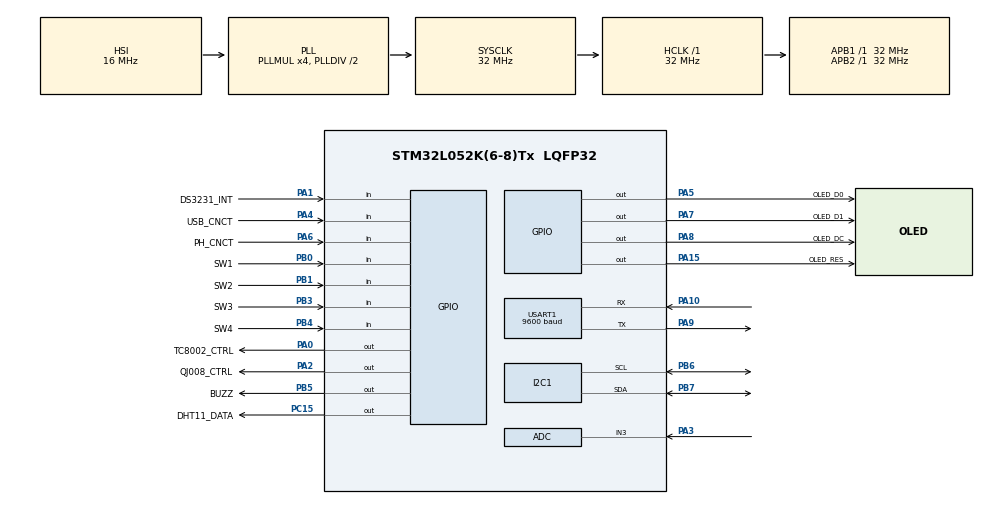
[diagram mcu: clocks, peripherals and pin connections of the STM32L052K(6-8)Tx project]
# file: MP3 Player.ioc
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ADC.ContinuousConvMode=ENABLE
ADC.SamplingTime=ADC_SAMPLETIME_160CYCLES_5
I2C1.Timing=0x00707CBB
Mcu.Family=STM32L0
Mcu.Name=STM32L052K(6-8)Tx
Mcu.Package=LQFP32
NVIC.TIM2_IRQn=true\:0\:0\:false\:false\:true\:true\:true\:true
NVIC.USART1_IRQn=true\:0\:0\:false\:false\:true\:true\:true\:true
PA0.GPIO_Label=TC8002_CTRL
PA0.GPIO_ModeDefaultOutputPP=GPIO_MODE_OUTPUT_OD
PA0.GPIO_PuPd=GPIO_NOPULL
PA0.GPIO_Speed=GPIO_SPEED_FREQ_VERY_HIGH
PA0.Signal=GPIO_Output
PA1.GPIO_Label=DS3231_INT
PA1.GPIO_PuPd=GPIO_PULLUP
PA1.Signal=GPIO_Input
PA10.Mode=Asynchronous
PA10.Signal=USART1_RX
PA13.Mode=Serial_Wire
PA13.Signal=SYS_SWDIO
PA14.Mode=Serial_Wire
PA14.Signal=SYS_SWCLK
PA15.GPIO_Label=OLED_RES
PA15.GPIO_Speed=GPIO_SPEED_FREQ_VERY_HIGH
PA15.Signal=GPIO_Output
PA2.GPIO_Label=QJ008_CTRL
PA2.GPIO_ModeDefaultOutputPP=GPIO_MODE_OUTPUT_OD
PA2.GPIO_PuPd=GPIO_NOPULL
PA2.GPIO_Speed=GPIO_SPEED_FREQ_VERY_HIGH
PA2.Signal=GPIO_Output
PA3.Mode=IN3
PA3.Signal=ADC_IN3
PA4.GPIO_Label=USB_CNCT
PA4.GPIO_PuPd=GPIO_PULLDOWN
PA4.Signal=GPIO_Input
PA5.GPIO_Label=OLED_D0
PA5.GPIO_Speed=GPIO_SPEED_FREQ_VERY_HIGH
PA5.Signal=GPIO_Output
PA6.GPIO_Label=PH_CNCT
PA6.Signal=GPIO_Input
PA7.GPIO_Label=OLED_D1
PA7.GPIO_Speed=GPIO_SPEED_FREQ_VERY_HIGH
PA7.Signal=GPIO_Output
PA8.GPIO_Label=OLED_DC
PA8.GPIO_Speed=GPIO_SPEED_FREQ_VERY_HIGH
PA8.Signal=GPIO_Output
PA9.Mode=Asynchronous
PA9.Signal=USART1_TX
PB0.GPIO_Label=SW1
PB0.GPIO_PuPd=GPIO_PULLUP
PB0.Signal=GPIO_Input
PB1.GPIO_Label=SW2
PB1.GPIO_PuPd=GPIO_PULLUP
PB1.Signal=GPIO_Input
PB3.GPIO_Label=SW3
PB3.GPIO_PuPd=GPIO_PULLUP
PB3.Signal=GPIO_Input
PB4.GPIO_Label=SW4
PB4.GPIO_PuPd=GPIO_PULLUP
PB4.Signal=GPIO_Input
PB5.GPIO_Label=BUZZ
PB5.GPIO_Speed=GPIO_SPEED_FREQ_VERY_HIGH
PB5.Signal=GPIO_Output
PB6.GPIO_Pu=GPIO_PULLUP
PB6.Mode=I2C
PB6.Signal=I2C1_SCL
PB7.GPIO_Pu=GPIO_PULLUP
PB7.Mode=I2C
PB7.Signal=I2C1_SDA
PC15-OSC32_OUT.GPIO_Label=DHT11_DATA
PC15-OSC32_OUT.GPIO_Speed=GPIO_SPEED_FREQ_VERY_HIGH
PC15-OSC32_OUT.PinState=GPIO_PIN_SET
PC15-OSC32_OUT.Signal=GPIO_Output
ProjectManager.HeapSize=0x200
ProjectManager.StackSize=0x400
ProjectManager.TargetToolchain=STM32CubeIDE
RCC.AHBFreq_Value=32000000
RCC.APB1Freq_Value=32000000
RCC.APB1TimFreq_Value=32000000
RCC.APB2Freq_Value=32000000
RCC.APB2TimFreq_Value=32000000
RCC.HCLKFreq_Value=32000000
RCC.HSI16_VALUE=16000000
RCC.HSI48_VALUE=48000000
RCC.HSI_VALUE=16000000
RCC.LSE_VALUE=32768
RCC.MSI_VALUE=2097000
RCC.PLLMUL=RCC_PLLMUL_4
RCC.SYSCLKFreq_VALUE=32000000
RCC.SYSCLKSource=RCC_SYSCLKSOURCE_PLLCLK
RCC.VCOOutputFreq_Value=64000000
TIM2.Period=10000-1
TIM2.Prescaler=32-1
USART1.BaudRate=9600
USART1.VirtualMode-Asynchronous=VM_ASYNC
VP_TIM2_VS_ClockSourceINT.Mode=Internal
board=custom

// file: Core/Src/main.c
/* USER CODE BEGIN Header */
/**
  ******************************************************************************
  * @file           : main.c
  * @brief          : Main program body
  ******************************************************************************
  * @attention
  *
  * Copyright (c) 2022 STMicroelectronics.
  * All rights reserved.
  *
  * This software is licensed under terms that can be found in the LICENSE file
  * in the root directory of this software component.
  * If no LICENSE file comes with this software, it is provided AS-IS.
  *
  ******************************************************************************
  */
/* USER CODE END Header */
#include "main.h"

/* USER CODE BEGIN Includes */
#include "User_Tasks.h"
/* USER CODE END Includes */

ADC_HandleTypeDef hadc;

I2C_HandleTypeDef hi2c1;

TIM_HandleTypeDef htim2;

UART_HandleTypeDef huart1;

void SystemClock_Config(void);
static void MX_GPIO_Init(void);
static void MX_ADC_Init(void);
static void MX_I2C1_Init(void);
static void MX_USART1_UART_Init(void);
static void MX_TIM2_Init(void);

int main(void)
{

  /* MCU Configuration--------------------------------------------------------*/

  /* Reset of all peripherals, Initializes the Flash interface and the Systick. */
  HAL_Init();

  /* Configure the system clock */
  SystemClock_Config();

  /* Initialize all configured peripherals */
  MX_GPIO_Init();
  MX_ADC_Init();
  MX_I2C1_Init();
  MX_USART1_UART_Init();
  MX_TIM2_Init();
  /* USER CODE BEGIN 2 */
  HAL_TIM_Base_Start_IT(&htim2);
  loop();
  /* USER CODE END 2 */

  /* Infinite loop */
  while (1)
  {

  }
}

void SystemClock_Config(void)
{
  RCC_OscInitTypeDef RCC_OscInitStruct = {0};
  RCC_ClkInitTypeDef RCC_ClkInitStruct = {0};
  RCC_PeriphCLKInitTypeDef PeriphClkInit = {0};

  /** Configure the main internal regulator output voltage
  */
  __HAL_PWR_VOLTAGESCALING_CONFIG(PWR_REGULATOR_VOLTAGE_SCALE1);

  /** Initializes the RCC Oscillators according to the specified parameters
  * in the RCC_OscInitTypeDef structure.
  */
  RCC_OscInitStruct.OscillatorType = RCC_OSCILLATORTYPE_HSI;
  RCC_OscInitStruct.HSIState = RCC_HSI_ON;
  RCC_OscInitStruct.HSICalibrationValue = RCC_HSICALIBRATION_DEFAULT;
  RCC_OscInitStruct.PLL.PLLState = RCC_PLL_ON;
  RCC_OscInitStruct.PLL.PLLSource = RCC_PLLSOURCE_HSI;
  RCC_OscInitStruct.PLL.PLLMUL = RCC_PLLMUL_4;
  RCC_OscInitStruct.PLL.PLLDIV = RCC_PLLDIV_2;
  if (HAL_RCC_OscConfig(&RCC_OscInitStruct) != HAL_OK)
  {
    Error_Handler();
  }

  /** Initializes the CPU, AHB and APB buses clocks
  */
  RCC_ClkInitStruct.ClockType = RCC_CLOCKTYPE_HCLK|RCC_CLOCKTYPE_SYSCLK
                              |RCC_CLOCKTYPE_PCLK1|RCC_CLOCKTYPE_PCLK2;
  RCC_ClkInitStruct.SYSCLKSource = RCC_SYSCLKSOURCE_PLLCLK;
  RCC_ClkInitStruct.AHBCLKDivider = RCC_SYSCLK_DIV1;
  RCC_ClkInitStruct.APB1CLKDivider = RCC_HCLK_DIV1;
  RCC_ClkInitStruct.APB2CLKDivider = RCC_HCLK_DIV1;

  if (HAL_RCC_ClockConfig(&RCC_ClkInitStruct, FLASH_LATENCY_1) != HAL_OK)
  {
    Error_Handler();
  }
  PeriphClkInit.PeriphClockSelection = RCC_PERIPHCLK_USART1|RCC_PERIPHCLK_I2C1;
  PeriphClkInit.Usart1ClockSelection = RCC_USART1CLKSOURCE_PCLK2;
  PeriphClkInit.I2c1ClockSelection = RCC_I2C1CLKSOURCE_PCLK1;
  if (HAL_RCCEx_PeriphCLKConfig(&PeriphClkInit) != HAL_OK)
  {
    Error_Handler();
  }
}

static void MX_ADC_Init(void)
{

  ADC_ChannelConfTypeDef sConfig = {0};

  /** Configure the global features of the ADC (Clock, Resolution, Data Alignment and number of conversion)
  */
  hadc.Instance = ADC1;
  hadc.Init.OversamplingMode = DISABLE;
  hadc.Init.ClockPrescaler = ADC_CLOCK_SYNC_PCLK_DIV2;
  hadc.Init.Resolution = ADC_RESOLUTION_12B;
  hadc.Init.SamplingTime = ADC_SAMPLETIME_160CYCLES_5;
  hadc.Init.ScanConvMode = ADC_SCAN_DIRECTION_FORWARD;
  hadc.Init.DataAlign = ADC_DATAALIGN_RIGHT;
  hadc.Init.ContinuousConvMode = ENABLE;
  hadc.Init.DiscontinuousConvMode = DISABLE;
  hadc.Init.ExternalTrigConvEdge = ADC_EXTERNALTRIGCONVEDGE_NONE;
  hadc.Init.ExternalTrigConv = ADC_SOFTWARE_START;
  hadc.Init.DMAContinuousRequests = DISABLE;
  hadc.Init.EOCSelection = ADC_EOC_SINGLE_CONV;
  hadc.Init.Overrun = ADC_OVR_DATA_PRESERVED;
  hadc.Init.LowPowerAutoWait = DISABLE;
  hadc.Init.LowPowerFrequencyMode = DISABLE;
  hadc.Init.LowPowerAutoPowerOff = DISABLE;
  if (HAL_ADC_Init(&hadc) != HAL_OK)
  {
    Error_Handler();
  }

  /** Configure for the selected ADC regular channel to be converted.
  */
  sConfig.Channel = ADC_CHANNEL_3;
  sConfig.Rank = ADC_RANK_CHANNEL_NUMBER;
  if (HAL_ADC_ConfigChannel(&hadc, &sConfig) != HAL_OK)
  {
    Error_Handler();
  }

}

static void MX_I2C1_Init(void)
{

  hi2c1.Instance = I2C1;
  hi2c1.Init.Timing = 0x00707CBB;
  hi2c1.Init.OwnAddress1 = 0;
  hi2c1.Init.AddressingMode = I2C_ADDRESSINGMODE_7BIT;
  hi2c1.Init.DualAddressMode = I2C_DUALADDRESS_DISABLE;
  hi2c1.Init.OwnAddress2 = 0;
  hi2c1.Init.OwnAddress2Masks = I2C_OA2_NOMASK;
  hi2c1.Init.GeneralCallMode = I2C_GENERALCALL_DISABLE;
  hi2c1.Init.NoStretchMode = I2C_NOSTRETCH_DISABLE;
  if (HAL_I2C_Init(&hi2c1) != HAL_OK)
  {
    Error_Handler();
  }

  /** Configure Analogue filter
  */
  if (HAL_I2CEx_ConfigAnalogFilter(&hi2c1, I2C_ANALOGFILTER_ENABLE) != HAL_OK)
  {
    Error_Handler();
  }

  /** Configure Digital filter
  */
  if (HAL_I2CEx_ConfigDigitalFilter(&hi2c1, 0) != HAL_OK)
  {
    Error_Handler();
  }

}

static void MX_TIM2_Init(void)
{

  TIM_ClockConfigTypeDef sClockSourceConfig = {0};
  TIM_MasterConfigTypeDef sMasterConfig = {0};

  htim2.Instance = TIM2;
  htim2.Init.Prescaler = 32-1;
  htim2.Init.CounterMode = TIM_COUNTERMODE_UP;
  htim2.Init.Period = 10000-1;
  htim2.Init.ClockDivision = TIM_CLOCKDIVISION_DIV1;
  htim2.Init.AutoReloadPreload = TIM_AUTORELOAD_PRELOAD_DISABLE;
  if (HAL_TIM_Base_Init(&htim2) != HAL_OK)
  {
    Error_Handler();
  }
  sClockSourceConfig.ClockSource = TIM_CLOCKSOURCE_INTERNAL;
  if (HAL_TIM_ConfigClockSource(&htim2, &sClockSourceConfig) != HAL_OK)
  {
    Error_Handler();
  }
  sMasterConfig.MasterOutputTrigger = TIM_TRGO_RESET;
  sMasterConfig.MasterSlaveMode = TIM_MASTERSLAVEMODE_DISABLE;
  if (HAL_TIMEx_MasterConfigSynchronization(&htim2, &sMasterConfig) != HAL_OK)
  {
    Error_Handler();
  }

}

static void MX_USART1_UART_Init(void)
{

  huart1.Instance = USART1;
  huart1.Init.BaudRate = 9600;
  huart1.Init.WordLength = UART_WORDLENGTH_8B;
  huart1.Init.StopBits = UART_STOPBITS_1;
  huart1.Init.Parity = UART_PARITY_NONE;
  huart1.Init.Mode = UART_MODE_TX_RX;
  huart1.Init.HwFlowCtl = UART_HWCONTROL_NONE;
  huart1.Init.OverSampling = UART_OVERSAMPLING_16;
  huart1.Init.OneBitSampling = UART_ONE_BIT_SAMPLE_DISABLE;
  huart1.AdvancedInit.AdvFeatureInit = UART_ADVFEATURE_NO_INIT;
  if (HAL_UART_Init(&huart1) != HAL_OK)
  {
    Error_Handler();
  }

}

static void MX_GPIO_Init(void)
{
  GPIO_InitTypeDef GPIO_InitStruct = {0};

  /* GPIO Ports Clock Enable */
  __HAL_RCC_GPIOC_CLK_ENABLE();
  __HAL_RCC_GPIOA_CLK_ENABLE();
  __HAL_RCC_GPIOB_CLK_ENABLE();

  /*Configure GPIO pin Output Level */
  HAL_GPIO_WritePin(DHT11_DATA_GPIO_Port, DHT11_DATA_Pin, GPIO_PIN_SET);

  /*Configure GPIO pin Output Level */
  HAL_GPIO_WritePin(GPIOA, TC8002_CTRL_Pin|QJ008_CTRL_Pin|OLED_D0_Pin|OLED_D1_Pin
                          |OLED_DC_Pin|OLED_RES_Pin, GPIO_PIN_RESET);

  /*Configure GPIO pin Output Level */
  HAL_GPIO_WritePin(BUZZ_GPIO_Port, BUZZ_Pin, GPIO_PIN_RESET);

  /*Configure GPIO pin : DHT11_DATA_Pin */
  GPIO_InitStruct.Pin = DHT11_DATA_Pin;
  GPIO_InitStruct.Mode = GPIO_MODE_OUTPUT_PP;
  GPIO_InitStruct.Pull = GPIO_NOPULL;
  GPIO_InitStruct.Speed = GPIO_SPEED_FREQ_VERY_HIGH;
  HAL_GPIO_Init(DHT11_DATA_GPIO_Port, &GPIO_InitStruct);

  /*Configure GPIO pins : TC8002_CTRL_Pin QJ008_CTRL_Pin */
  GPIO_InitStruct.Pin = TC8002_CTRL_Pin|QJ008_CTRL_Pin;
  GPIO_InitStruct.Mode = GPIO_MODE_OUTPUT_OD;
  GPIO_InitStruct.Pull = GPIO_NOPULL;
  GPIO_InitStruct.Speed = GPIO_SPEED_FREQ_VERY_HIGH;
  HAL_GPIO_Init(GPIOA, &GPIO_InitStruct);

  /*Configure GPIO pin : DS3231_INT_Pin */
  GPIO_InitStruct.Pin = DS3231_INT_Pin;
  GPIO_InitStruct.Mode = GPIO_MODE_INPUT;
  GPIO_InitStruct.Pull = GPIO_PULLUP;
  HAL_GPIO_Init(DS3231_INT_GPIO_Port, &GPIO_InitStruct);

  /*Configure GPIO pin : USB_CNCT_Pin */
  GPIO_InitStruct.Pin = USB_CNCT_Pin;
  GPIO_InitStruct.Mode = GPIO_MODE_INPUT;
  GPIO_InitStruct.Pull = GPIO_PULLDOWN;
  HAL_GPIO_Init(USB_CNCT_GPIO_Port, &GPIO_InitStruct);

  /*Configure GPIO pins : OLED_D0_Pin OLED_D1_Pin OLED_DC_Pin OLED_RES_Pin */
  GPIO_InitStruct.Pin = OLED_D0_Pin|OLED_D1_Pin|OLED_DC_Pin|OLED_RES_Pin;
  GPIO_InitStruct.Mode = GPIO_MODE_OUTPUT_PP;
  GPIO_InitStruct.Pull = GPIO_NOPULL;
  GPIO_InitStruct.Speed = GPIO_SPEED_FREQ_VERY_HIGH;
  HAL_GPIO_Init(GPIOA, &GPIO_InitStruct);

  /*Configure GPIO pin : PH_CNCT_Pin */
  GPIO_InitStruct.Pin = PH_CNCT_Pin;
  GPIO_InitStruct.Mode = GPIO_MODE_INPUT;
  GPIO_InitStruct.Pull = GPIO_NOPULL;
  HAL_GPIO_Init(PH_CNCT_GPIO_Port, &GPIO_InitStruct);

  /*Configure GPIO pins : SW1_Pin SW2_Pin SW3_Pin SW4_Pin */
  GPIO_InitStruct.Pin = SW1_Pin|SW2_Pin|SW3_Pin|SW4_Pin;
  GPIO_InitStruct.Mode = GPIO_MODE_INPUT;
  GPIO_InitStruct.Pull = GPIO_PULLUP;
  HAL_GPIO_Init(GPIOB, &GPIO_InitStruct);

  /*Configure GPIO pin : BUZZ_Pin */
  GPIO_InitStruct.Pin = BUZZ_Pin;
  GPIO_InitStruct.Mode = GPIO_MODE_OUTPUT_PP;
  GPIO_InitStruct.Pull = GPIO_NOPULL;
  GPIO_InitStruct.Speed = GPIO_SPEED_FREQ_VERY_HIGH;
  HAL_GPIO_Init(BUZZ_GPIO_Port, &GPIO_InitStruct);

}

void Error_Handler(void)
{
  __disable_irq();
  while (1)
  {
  }
}
